# PIC32MX254F128D register map
Vendor: Microchip
Registers are 32-bit, read-write, reset 0x0 unless marked. A register's access mark holds for its fields unless they carry their own. Addresses are absolute, and some are shared; only a register's first bit layout is shown; [hi:lo] are bit positions; {n}, {i} and the like mark numbered series.

## RPORx
{0x1F80FB00+4i} RPA{i}R (i=0..4)
  [3:0] RPA{i}R
0x1F80FB20 RPA8R
  [3:0] RPA8R
0x1F80FB24 RPA9R
  [3:0] RPA9R
{0x1F80FB2C+4i} RPB{i}R (i=0..11)
  [3:0] RPB{i}R
{0x1F80FB2C+4i} RPB{i}R (i=13..15)
  [3:0] RPB{i}R
{0x1F80FB6C+4i} RPC{i}R (i=0..9)
  [3:0] RPC{i}R

## HLVD
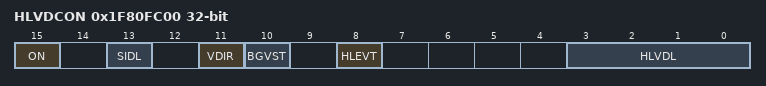
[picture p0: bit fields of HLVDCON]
0x1F80FC00 HLVDCON
  [15] ON, [13] SIDL, [11] VDIR, [10] BGVST, [8] HLEVT, [3:0] HLVDL

## INT
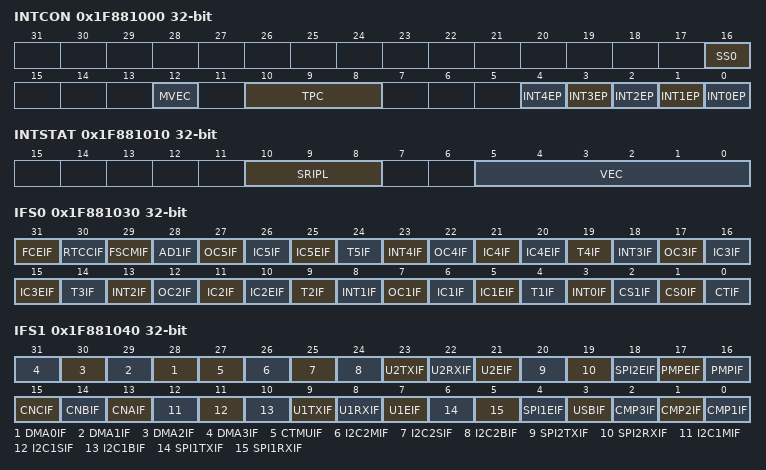
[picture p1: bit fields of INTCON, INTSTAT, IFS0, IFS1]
0x1F881000 INTCON
  [16] SS0, [12] MVEC, [10:8] TPC, [n] INT{n}EP (n=0..4)
0x1F881010 INTSTAT
  [10:8] SRIPL, [5:0] VEC
0x1F881020 IPTMR
0x1F881030 IFS0 reset not defined — (power-on value 00000x0000x0000x0000000000000000)
  [31] FCEIF, [30] RTCCIF, [29] FSCMIF, [28] AD1IF, [5n+2] OC{n}IF (n=1..5), [5n+1] IC{n}IF (n=1..5), [5n] IC{n}EIF (n=1..5), [5n-1] T{n}IF (n=1..5), [5n+3] INT{n}IF (n=0..4), [2] CS1IF, [1] CS0IF, [0] CTIF
0x1F881040 IFS1 reset not defined — (power-on value xxxxxx00xxxx00000000000000000000)
  [n+28] DMA{n}IF (n=0..3), [27] CTMUIF, [26] I2C2MIF, [25] I2C2SIF, [24] I2C2BIF, [23] U2TXIF, [22] U2RXIF, [21] U2EIF, [20] SPI2TXIF, [19] SPI2RXIF, [18] SPI2EIF, [17] PMPEIF, [16] PMPIF, [15] CNCIF, [14] CNBIF, [13] CNAIF, [12] I2C1MIF, [11] I2C1SIF, [10] I2C1BIF, [9] U1TXIF, [8] U1RXIF, [7] U1EIF, [6] SPI1TXIF, [5] SPI1RXIF, [4] SPI1EIF, [3] USBIF, [2] CMP3IF, [1] CMP2IF, [0] CMP1IF
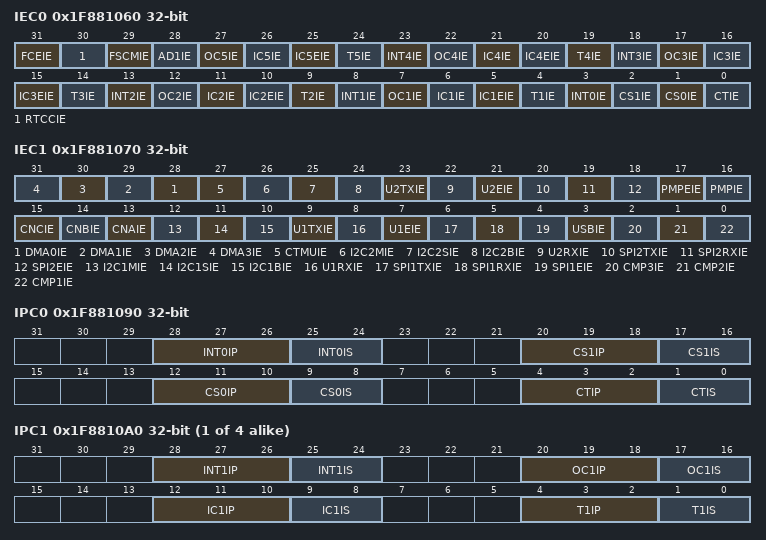
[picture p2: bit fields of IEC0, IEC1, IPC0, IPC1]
0x1F881060 IEC0 reset not defined — (power-on value 00000x0000x0000x0000000000000000)
  [31] FCEIE, [30] RTCCIE, [29] FSCMIE, [28] AD1IE, [5n+2] OC{n}IE (n=1..5), [5n+1] IC{n}IE (n=1..5), [5n] IC{n}EIE (n=1..5), [5n-1] T{n}IE (n=1..5), [5n+3] INT{n}IE (n=0..4), [2] CS1IE, [1] CS0IE, [0] CTIE
0x1F881070 IEC1 reset not defined — (power-on value xxxxxx-0xxxx-0000000000000000000)
  [n+28] DMA{n}IE (n=0..3), [27] CTMUIE, [26] I2C2MIE, [25] I2C2SIE, [24] I2C2BIE, [23] U2TXIE, [22] U2RXIE, [21] U2EIE, [20] SPI2TXIE, [19] SPI2RXIE, [18] SPI2EIE, [17] PMPEIE, [16] PMPIE, [15] CNCIE, [14] CNBIE, [13] CNAIE, [12] I2C1MIE, [11] I2C1SIE, [10] I2C1BIE, [9] U1TXIE, [8] U1RXIE, [7] U1EIE, [6] SPI1TXIE, [5] SPI1RXIE, [4] SPI1EIE, [3] USBIE, [2] CMP3IE, [1] CMP2IE, [0] CMP1IE
0x1F881090 IPC0
  [28:26] INT0IP, [25:24] INT0IS, [20:18] CS1IP, [17:16] CS1IS, [12:10] CS0IP, [9:8] CS0IS, [4:2] CTIP, [1:0] CTIS
{0x1F881090+0x10*i} IPC{i} (i=1..4)
  [28:26] INT{i}IP, [25:24] INT{i}IS, [20:18] OC{i}IP, [17:16] OC{i}IS, [12:10] IC{i}IP, [9:8] IC{i}IS, [4:2] T{i}IP, [1:0] T{i}IS
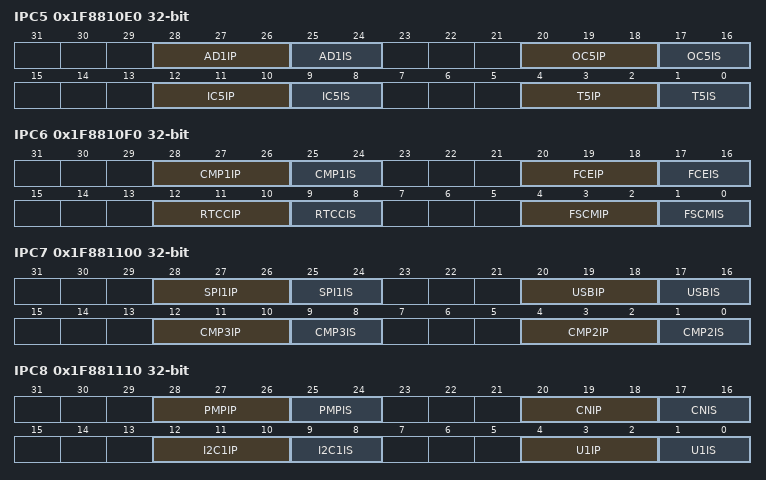
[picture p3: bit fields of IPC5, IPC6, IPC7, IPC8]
0x1F8810E0 IPC5
  [28:26] AD1IP, [25:24] AD1IS, [20:18] OC5IP, [17:16] OC5IS, [12:10] IC5IP, [9:8] IC5IS, [4:2] T5IP, [1:0] T5IS
0x1F8810F0 IPC6
  [28:26] CMP1IP, [25:24] CMP1IS, [20:18] FCEIP, [17:16] FCEIS, [12:10] RTCCIP, [9:8] RTCCIS, [4:2] FSCMIP, [1:0] FSCMIS
0x1F881100 IPC7
  [28:26] SPI1IP, [25:24] SPI1IS, [20:18] USBIP, [17:16] USBIS, [12:10] CMP3IP, [9:8] CMP3IS, [4:2] CMP2IP, [1:0] CMP2IS
0x1F881110 IPC8
  [28:26] PMPIP, [25:24] PMPIS, [20:18] CNIP, [17:16] CNIS, [12:10] I2C1IP, [9:8] I2C1IS, [4:2] U1IP, [1:0] U1IS
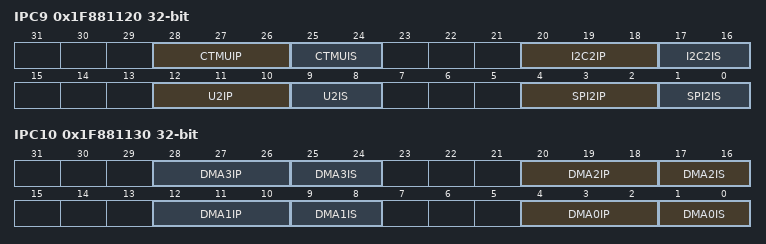
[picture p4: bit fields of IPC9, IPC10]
0x1F881120 IPC9
  [28:26] CTMUIP, [25:24] CTMUIS, [20:18] I2C2IP, [17:16] I2C2IS, [12:10] U2IP, [9:8] U2IS, [4:2] SPI2IP, [1:0] SPI2IS
0x1F881130 IPC10 reset not defined — (power-on value ---xxxxx---xxxxx---xxxxx---xxxxx)
  [8n+4:8n+2] DMA{n}IP (n=0..3), [8n+1:8n] DMA{n}IS (n=0..3)

## BMX
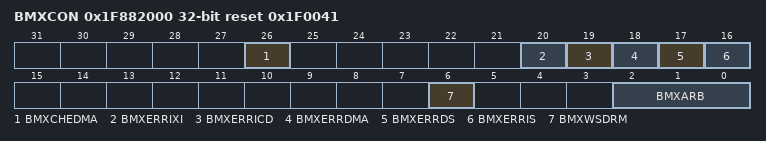
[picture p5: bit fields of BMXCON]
0x1F882000 BMXCON reset 0x1F0041
  [26] BMXCHEDMA, [20] BMXERRIXI, [19] BMXERRICD, [18] BMXERRDMA, [17] BMXERRDS, [16] BMXERRIS, [6] BMXWSDRM, [2:0] BMXARB
0x1F882010 BMXDKPBA
0x1F882020 BMXDUDBA
0x1F882030 BMXDUPBA
0x1F882040 BMXDRMSZ ro reset 0x20000
0x1F882050 BMXPUPBA
0x1F882060 BMXPFMSZ ro reset 0x80000
0x1F882070 BMXBOOTSZ ro reset 0x3000

## DMAC
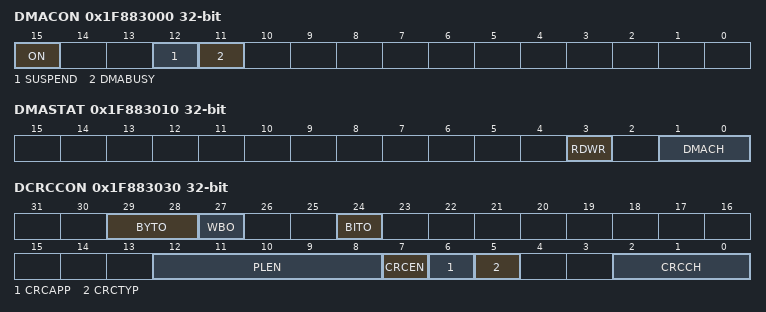
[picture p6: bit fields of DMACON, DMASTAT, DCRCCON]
0x1F883000 DMACON reset not defined — (power-on value ----------------00-0x-----------)
  [15] ON, [12] SUSPEND, [11] DMABUSY
0x1F883010 DMASTAT
  [3] RDWR, [1:0] DMACH
0x1F883020 DMAADDR ro
0x1F883030 DCRCCON reset not defined — (power-on value --xxx--x-----------xxxxx00x--000)
  [29:28] BYTO, [27] WBO, [24] BITO, [12:8] PLEN, [7] CRCEN, [6] CRCAPP, [5] CRCTYP, [2:0] CRCCH
0x1F883040 DCRCDATA
0x1F883050 DCRCXOR
